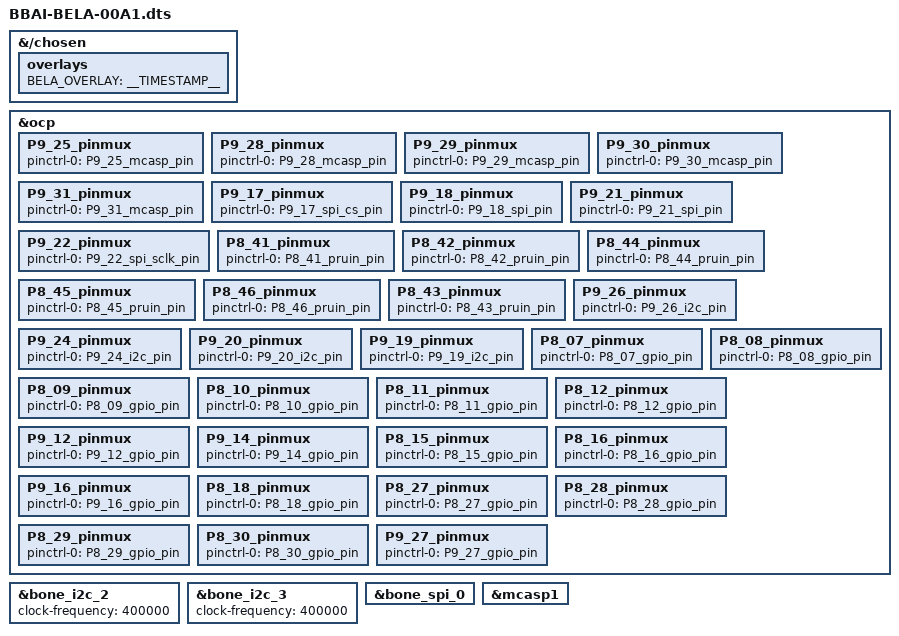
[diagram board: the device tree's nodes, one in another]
/*
 * Copyright (C) 2021 Dhruva Gole <goledhruva@gmail.com>
 *
 * This program is free software; you can redistribute it and/or modify
 * it under the terms of the GNU General Public License version 2 as
 * published by the Free Software Foundation.
 */

/dts-v1/;
/plugin/;

/*
 * Helper to show loaded overlays under: /proc/device-tree/chosen/overlays/
 */
&{/chosen} {
    overlays {
        BELA_OVERLAY = __TIMESTAMP__;
    };
};

&ocp {  //fragment@0
    /* Pinmux for McASP1 (audio i/o) */
    P9_25_pinmux { pinctrl-0 = <&P9_25_mcasp_pin>;  };  /* xref_clk0.mcasp1_ahclkx */
    P9_28_pinmux { pinctrl-0 = <&P9_28_mcasp_pin>;  };  /* mcasp1_axr11.mcasp1_axr11 */
    P9_29_pinmux { pinctrl-0 = <&P9_29_mcasp_pin>;  };  /* mcasp1_fsx.mcasp1_fsx, mcasp1_axr9.off */
    P9_30_pinmux { pinctrl-0 = <&P9_30_mcasp_pin>;  };  /* mcasp1_axr10.mcasp1_axr10 */
    P9_31_pinmux { pinctrl-0 = <&P9_31_mcasp_pin>;  };  /* mcasp1_aclkx.mcasp1_aclkx, mcasp1_axr8.off */

    /* McSPI */
    P9_17_pinmux { pinctrl-0 = <&P9_17_spi_cs_pin>;  }; /* spi2_cs0.spi2_cs0, mcasp1_axr1.off */
    P9_18_pinmux { pinctrl-0 = <&P9_18_spi_pin>; }; /* spi2_d0.spi2_d0, mcasp1_axr0.off */
    P9_21_pinmux { pinctrl-0 = <&P9_21_spi_pin>;  }; /* spi2_d1.spi2_d1, vin1a_vsync0.off */
    P9_22_pinmux { pinctrl-0 = <&P9_22_spi_sclk_pin>;  };   /* spi2_sclk.spi2_sclk, xref_clk2.off */

    /* 	pinmux_bela_pru_pins */
    P8_41_pinmux { pinctrl-0 = <&P8_41_pruin_pin>; };	/* vout1_d4.pr2_pru0_gpi1 */
    P8_42_pinmux { pinctrl-0 = <&P8_42_pruin_pin>; };	/* vout1_d5.pr2_pru0_gpi2 */
    P8_44_pinmux { pinctrl-0 = <&P8_44_pruin_pin>; };	/* vout1_d3.pr2_pru0_gpi0 */
    P8_45_pinmux { pinctrl-0 = <&P8_45_pruin_pin>; };	/* vout1_d0.pr2_pru1_gpi18 */
    P8_46_pinmux { pinctrl-0 = <&P8_46_pruin_pin>; };	/* vout1_d1.pr2_pru1_gpi19 */
    P8_43_pinmux { pinctrl-0 = <&P8_43_pruin_pin>; };	/* vout1_d2.pr2_pru1_gpi20 */

    /* Pinmux for i2c on Bela header */
    P9_26_pinmux { pinctrl-0 = <&P9_26_i2c_pin>; }; /* gpio6_14.i2c3_sda */
    P9_24_pinmux { pinctrl-0 = <&P9_24_i2c_pin>; };  /* gpio6_15.i2c3_scl */

    // Pinmux for i2c2 for Bela codec
    P9_20_pinmux { pinctrl-0 = <&P9_20_i2c_pin>; };  /* gpmc_a1.i2c4_sda  */
    P9_19_pinmux { pinctrl-0 = <&P9_19_i2c_pin>; };  /* gpmc_a0.i2c4_scl */

    /* pinmux for BB digitals */
    // refer https://github.com/BelaPlatform/bb.org-overlays/blob/master/src/arm/BB-BELA-00A1.dts#L143
    P8_07_pinmux { pinctrl-0 = <&P8_07_gpio_pin>; };  /* mcasp1_axr14.gpio6_5 */
    P8_08_pinmux { pinctrl-0 = <&P8_08_gpio_pin>; };  /*  */
    P8_09_pinmux { pinctrl-0 = <&P8_09_gpio_pin>; };  /*  */
    P8_10_pinmux { pinctrl-0 = <&P8_10_gpio_pin>; };  /*  */
    P8_11_pinmux { pinctrl-0 = <&P8_11_gpio_pin>; };  /*  */
    P8_12_pinmux { pinctrl-0 = <&P8_12_gpio_pin>; };  /*  */
    P9_12_pinmux { pinctrl-0 = <&P9_12_gpio_pin>; };  /* mcasp1_aclkr.gpio5_0 */
    P9_14_pinmux { pinctrl-0 = <&P9_14_gpio_pin>; };  /* mcasp1_aclkr.gpio5_0 */
    P8_15_pinmux { pinctrl-0 = <&P8_15_gpio_pin>; };  /*  */
    P8_16_pinmux { pinctrl-0 = <&P8_16_gpio_pin>; };  /*  */
    P9_16_pinmux { pinctrl-0 = <&P9_16_gpio_pin>; };  /*  */
    P8_18_pinmux { pinctrl-0 = <&P8_18_gpio_pin>; };  /*  */
    P8_27_pinmux { pinctrl-0 = <&P8_27_gpio_pin>; };  /*  */
    P8_28_pinmux { pinctrl-0 = <&P8_28_gpio_pin>; };  /*  */
    P8_29_pinmux { pinctrl-0 = <&P8_29_gpio_pin>; };  /*  */
    P8_30_pinmux { pinctrl-0 = <&P8_30_gpio_pin>; };  /*  */

	/* Pinmux for Bela Button */
    P9_27_pinmux { pinctrl-0 = <&P9_27_gpio_pin>; };  /* vin2a_d14.gpio4_15, mcasp1_fsr.off */
};

&bone_i2c_2 {   //fragment@10
    status = "okay";
    clock-frequency = <400000>;
};

&bone_i2c_3{   //fragment@10
    status = "okay";
    clock-frequency = <400000>;
};

&bone_spi_0{
    status = "okay";
};

&mcasp1 {   //fragment@4
        status = "okay";
};
